# SIM3L168_A register map
File version: 1
CPU: 
Registers are 32-bit, read-write, reset 0x0 unless marked. A register's access mark holds for its fields unless they carry their own. Offsets are from the block's base; [hi:lo] are bit positions; {n}, {i} and the like mark numbered series; 'fields as' and 'values as' point back to an identical list; <NAME> marks a mode.

## SARADC_0
Base 0x4001A000
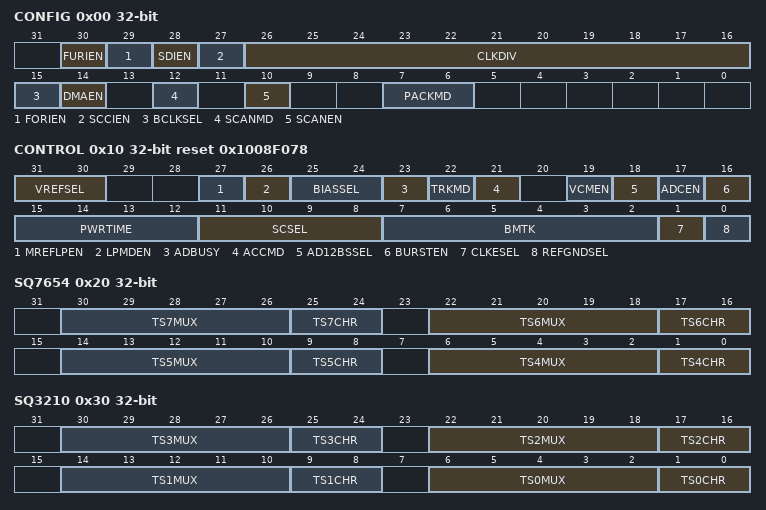
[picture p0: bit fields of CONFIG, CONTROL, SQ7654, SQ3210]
0x00 CONFIG — Module Configuration
  [30] FURIEN — FIFO Underrun Interrupt Enable.
    0=DISABLED (Disable the data FIFO underrun interrupt.); 1=ENABLED (Enable the data FIFO underrun interrupt.)
  [29] FORIEN — FIFO Overrun Interrupt Enable.
    0=DISABLED (Disable the data FIFO overrun interrupt.); 1=ENABLED (Enable the data FIFO overrun interrupt.)
  [28] SDIEN — Scan Done Interrupt Enable.
    0=DISABLED (Disable the ADC scan complete interrupt.); 1=ENABLED (Enable the ADC scan complete interrupt.)
  [27] SCCIEN — Single Conversion Complete Interrupt Enable.
    0=DISABLED (Disable the ADC single data conversion complete interrupt.); 1=ENABLED (Enable the ADC single data conversion complete interrupt.)
  [26:16] CLKDIV — SAR Clock Divider.
  [15] BCLKSEL — Burst Mode Clock Select.
    0=LPOSC0 (Burst mode uses the Low Power Oscillator.); 1=APB (Burst mode uses the APB clock.)
  [14] DMAEN — DMA Interface Enable .
    0=DISABLED (Disable the ADC module DMA interface.); 1=ENABLED (Enable the ADC module DMA interface.)
  [12] SCANMD — Scan Mode Select.
    0=ONCE (The channel sequencer will cycle through all of the specified time slots once.); 1=LOOP (The channel sequencer will cycle through all of the specified time slots in a loop until SCANEN is cleared to 0.)
  [10] SCANEN — Scan Mode Enable.
    0=DISABLED (Disable ADC scan mode.); 1=ENABLED (Enable ADC scan mode. The ADC will scan through the defined time slots in sequence on every start of conversion.)
  [7:6] PACKMD — Output Packing Mode.
    0=UPPER_ONLY (Data is written to the upper half-word and the lower half-word is filled with 0's. An SCI interrupt is triggered when data is written, if enabled.); 1=LOWER_ONLY (Data is written to the lower half-word, and the upper half-word is filled with 0's. An SCI interrupt is triggered when data is written, if enabled.); 2=UPPER_FIRST (Two data words are packed into the register with the upper half-word representing the earlier data, and the lower half-word representing the later data. The ADC write to the lower half-word will trigger the SCI interrupt, if enabled.); 3=LOWER_FIRST (Two data words are packed into the register with the lower half-word representing the earlier data, and the upper half-word representing the later data. The ADC write to the upper half-word will trigger the SCI interrupt, if enabled.)
0x10 CONTROL reset 0x1008F078 — Measurement Control
  [31:30] VREFSEL — Voltage Reference Select.
    0=INTERNAL_VREF (Select the internal, dedicated SARADC voltage reference as the ADC reference.); 1=VDD (Select the VDD pin as the ADC reference.); 2=LDO_OUT (Select the output of the internal LDO regulator (~1.8 V) as the ADC reference.); 3=EXTERNAL_VREF (Select the VREF pin as the ADC reference. This option is used for either an external VREF or the on-chip VREF driving out to the VREF pin.)
  [27] MREFLPEN — MUX and VREF Low Power Enable.
    0=DISABLED (Disable low power mode.); 1=ENABLED (Enable low power mode (SAR clock <= 4 MHz).)
  [26] LPMDEN — Low Power Mode Enable.
    0=DISABLED (Disable low power mode.); 1=ENABLED (Enable low power mode (requires extended tracking time).)
  [25:24] BIASSEL — Bias Power Select.
    0=MODE0 (Select bias current mode 0. Recommended to use modes 1, 2, or 3.); 1=MODE1 (Select bias current mode 1 (SARCLK = 16 MHz).); 2=MODE2 (Select bias current mode 2.); 3=MODE3 (Select bias current mode 3 (SARCLK = 4 MHz).)
  [23] ADBUSY — ADC Busy.
  [22] TRKMD — ADC Tracking Mode.
    0=NORMAL (Normal Tracking Mode: When the ADC is enabled, a conversion begins immediately following the start-of-conversion signal.); 1=DELAYED (Delayed Tracking Mode: When the ADC is enabled, a conversion begins 3 SAR clock cycles following the start-of-conversion signal. The ADC is allowed to track during this time.)
  [21] ACCMD — Accumulation Mode.
    0=ACCUMULATE (Conversions will be accumulated for the specified number of cycles in burst mode according to the channel configuration.); 1=REPEAT (Conversions will not be accumulated in burst mode.)
  [19] VCMEN — Common Mode Buffer Enable.
    0=DISABLED (Disable the common mode buffer.); 1=ENABLED (Enable the common mode buffer.)
  [18] AD12BSSEL — 12-Bit Mode Sample Select.
    0=FOUR (The ADC re-samples the input before each of the four conversions.); 1=ONE (The ADC samples once before the first conversion and converts four times.)
  [17] ADCEN — ADC Enable.
    0=DISABLED (Disable the ADC (low-power shutdown).); 1=ENABLED (Enable the ADC (active and ready for data conversions).)
  [16] BURSTEN — Burst Mode Enable.
    0=DISABLED (Disable burst mode.); 1=ENABLED (Enable burst mode.)
  [15:12] PWRTIME — Burst Mode Power Up Time.
  [11:8] SCSEL — Start-Of-Conversion Source Select.
    {v}=ADCNT{v} (An ADC conversion triggers from the <dict>ADCnT{v}</dict> trigger source.) (v=0..15)
  [7:2] BMTK — Burst Mode Tracking Time.
  [1] CLKESEL — Sampling Clock Edge Select.
    0=RISING (Select the rising edge of the APB clock.); 1=FALLING (Select the falling edge of the APB clock.)
  [0] REFGNDSEL — Reference Ground Select.
    0=INTERNAL (The internal device ground is used as the ground reference for ADC conversions.); 1=EXTERNAL (The VREFGND pin is used as the ground reference for ADC conversions.)
0x20 SQ7654 — Channel Sequencer Time Slots 4-7 Setup
  [8n-26:8n-30] TS{n}MUX (n=4..7) — Time Slot {n} Input Channel.
    0=ADCN0 (Select channel <dict>ADCn.0</dict>.); 1=ADCN1 (Select channel <dict>ADCn.1</dict>.); 2=ADCN2 (Select channel <dict>ADCn.2</dict>.); 3=ADCN3 (Select channel <dict>ADCn.3</dict>.); 4=ADCN4 (Select channel <dict>ADCn.4</dict>.); 5=ADCN5 (Select channel <dict>ADCn.5</dict>.); 6=ADCN6 (Select channel <dict>ADCn.6</dict>.); 7=ADCN7 (Select channel <dict>ADCn.7</dict>.); 8=ADCN8 (Select channel <dict>ADCn.8</dict>.); 9=ADCN9 (Select channel <dict>ADCn.9</dict>.); 10=ADCN10 (Select channel <dict>ADCn.10</dict>.); 11=ADCN11 (Select channel <dict>ADCn.11</dict>.); 12=ADCN12 (Select channel <dict>ADCn.12</dict>.); 13=ADCN13 (Select channel <dict>ADCn.13</dict>.); 14=ADCN14 (Select channel <dict>ADCn.14</dict>.); 15=ADCN15 (Select channel <dict>ADCn.15</dict>.); 16=ADCN16 (Select channel <dict>ADCn.16</dict>.); 17=ADCN17 (Select channel <dict>ADCn.17</dict>.); 18=ADCN18 (Select channel <dict>ADCn.18</dict>.); 19=ADCN19 (Select channel <dict>ADCn.19</dict>.); 20=ADCN20 (Select channel <dict>ADCn.20</dict>.); 21=ADCN21 (Select channel <dict>ADCn.21</dict>.); 22=ADCN22 (Select channel <dict>ADCn.22</dict>.); 23=ADCN23 (Select channel <dict>ADCn.23</dict>.); 24=ADCN24 (Select channel <dict>ADCn.24</dict>.); 25=ADCN25 (Select channel <dict>ADCn.25</dict>.); 26=ADCN26 (Select channel <dict>ADCn.26</dict>.); 27=ADCN27 (Select channel <dict>ADCn.27</dict>.); 28=ADCN28 (Select channel <dict>ADCn.28</dict>.); 29=ADCN29 (Select channel <dict>ADCn.29</dict>.); 30=ADCN30 (Select channel <dict>ADCn.30</dict>.); 31=END (None - End the sequence.)
  [8n-31:8n-32] TS{n}CHR (n=4..7) — Time Slot {n} Conversion Characteristic.
    {v}=CC{v} (Select conversion characteristic {v} for time slot {n}.) (v=0..3)
0x30 SQ3210 — Channel Sequencer Time Slots 0-3 Setup
  [8n+6:8n+2] TS{n}MUX (n=0..3) — Time Slot {n} Input Channel.
    values as SQ7654.TS4MUX
  [8n+1:8n] TS{n}CHR (n=0..3) — Time Slot {n} Conversion Characteristic.
    values as SQ7654.TS4CHR
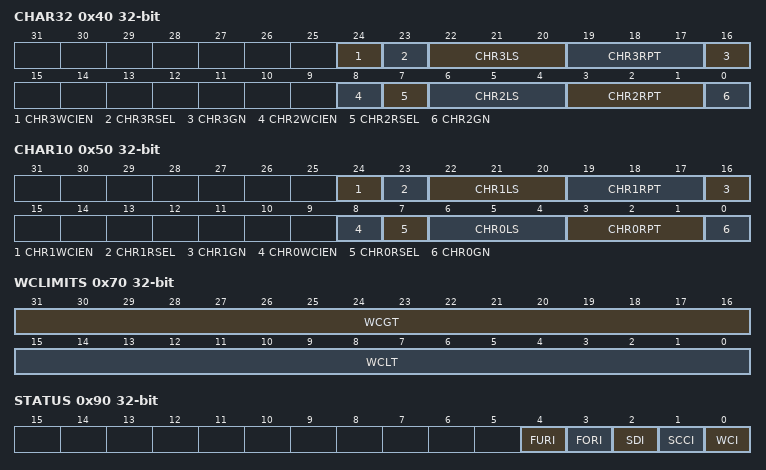
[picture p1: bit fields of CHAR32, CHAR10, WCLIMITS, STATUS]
0x40 CHAR32 — Conversion Characteristic 2 and 3 Setup
  [24] CHR3WCIEN — Conversion Characteristic 3 Window Comparator Interrupt Enable.
    0=DISABLED (Disable window comparison interrupts.); 1=ENABLED (Enabled window comparison interrupts. The window comparator will be used to check the ADC result on channels that use this characteristic.)
  [23] CHR3RSEL — Conversion Characteristic 3 Resolution Selection.
    0=B10 (Select 10-bit Mode.); 1=B12 (Select 12-bit Mode (burst mode must be enabled).)
  [22:20] CHR3LS — Conversion Characteristic 3 Left-Shift Bits.
  [19:17] CHR3RPT — Conversion Characteristic 3 Repeat Counter.
    0=ACC1 (Accumulate one sample.); 1=ACC4 (Accumulate four samples.); 2=ACC8 (Accumulate eight samples.); 3=ACC16 (Accumulate sixteen samples.); 4=ACC32 (Accumulate thirty-two samples (10-bit mode only).); 5=ACC64 (Accumulate sixty-four samples (10-bit mode only).)
  [16] CHR3GN — Conversion Characteristic 3 Gain.
    0=UNITY (The on-chip PGA gain is 1.); 1=HALF (The on-chip PGA gain is 0.5.)
  [8] CHR2WCIEN — Conversion Characteristic 2 Window Comparator Interrupt Enable.
    values as CHR3WCIEN
  [7] CHR2RSEL — Conversion Characteristic 2 Resolution Selection.
    values as CHR3RSEL
  [6:4] CHR2LS — Conversion Characteristic 2 Left-Shift Bits.
  [3:1] CHR2RPT — Conversion Characteristic 2 Repeat Counter.
    values as CHR3RPT
  [0] CHR2GN — Conversion Characteristic 2 Gain.
    values as CHR3GN
0x50 CHAR10 — Conversion Characteristic 0 and 1 Setup
  [24] CHR1WCIEN — Conversion Characteristic 1 Window Comparator Interrupt Enable.
    values as CHAR32.CHR3WCIEN
  [23] CHR1RSEL — Conversion Characteristic 1 Resolution Selection.
    values as CHAR32.CHR3RSEL
  [22:20] CHR1LS — Conversion Characteristic 1 Left-Shift Bits.
  [19:17] CHR1RPT — Conversion Characteristic 1 Repeat Counter.
    values as CHAR32.CHR3RPT
  [16] CHR1GN — Conversion Characteristic 1 Gain.
    values as CHAR32.CHR3GN
  [8] CHR0WCIEN — Conversion Characteristic 0 Window Comparator Interrupt Enable.
    values as CHAR32.CHR3WCIEN
  [7] CHR0RSEL — Conversion Characteristic 0 Resolution Selection.
    values as CHAR32.CHR3RSEL
  [6:4] CHR0LS — Conversion Characteristic 0 Left-Shift Bits.
  [3:1] CHR0RPT — Conversion Characteristic 0 Repeat Counter.
    values as CHAR32.CHR3RPT
  [0] CHR0GN — Conversion Characteristic 0 Gain.
    values as CHAR32.CHR3GN
0x60 DATA — Output Data Word
  [31:0] DATA ro — Output Data Word.
0x70 WCLIMITS — Window Comparator Limits
  [31:16] WCGT — Greater-Than Window Comparator Limit.
  [15:0] WCLT — Less-Than Window Comparator Limit.
0x80 ACC — Accumulator Initial Value
  [15:0] ACC wo — Accumulator Initial Value.
0x90 STATUS — Module Status
  [4] FURI — FIFO Underrun Interrupt.
    0=NOT_SET (Read: A data FIFO underrun interrupt has not occurred. Write: Clear the interrupt.); 1=SET (Read: A data FIFO underrun interrupt occurred. Write: Force a data FIFO underrun interrupt.)
  [3] FORI — FIFO Overrun Interrupt.
    0=NOT_SET (Read: A data FIFO overrun interrupt has not occurred. Write: Clear the interrupt.); 1=SET (Read: A data FIFO overrun interrupt occurred. Write: Force a data FIFO overrun interrupt.)
  [2] SDI — Scan Done Interrupt.
    0=NOT_SET (Read: A scan done interrupt has not occurred. Write: Clear the interrupt.); 1=SET (Read: A scan done interrupt occurred. Write: Force a scan done interrupt.)
  [1] SCCI — Single Conversion Complete Interrupt.
    0=NOT_SET (Read: A single data conversion interrupt has not occurred. Write: Clear the interrupt.); 1=SET (Read: A single data conversion interrupt occurred. Write: Force a single data conversion interrupt.)
  [0] WCI — Window Compare Interrupt.
    0=NOT_SET (Read: A window compare interrupt has not occurred. Write: Clear the interrupt.); 1=SET (Read: A window compare interrupt occurred. Write: Force a window compare interrupt.)
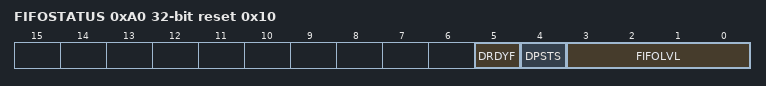
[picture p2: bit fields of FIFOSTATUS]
0xA0 FIFOSTATUS reset 0x10
  [5] DRDYF ro — Data Ready Flag.
    0=NOT_SET (New data is not produced yet.); 1=SET (New data is ready.)
  [4] DPSTS ro — Data Packing Status.
    0=LOWER (The next ADC conversion will be written to the lower half-word.); 1=UPPER (The next ADC conversion will be written to the upper half-word.)
  [3:0] FIFOLVL ro — FIFO Level.
